# GATECAP_DEMO_DEVICE register map
Stub device the gatecap bus-explorer example explores
Registers are 32-bit, read-only, no defined reset value unless marked. A register's access mark holds for its fields unless they carry their own. Offsets are from the block's base; lines under a group give offsets from that group; [hi:lo] are bit positions; {n}, {i} and the like mark numbered series; 'fields as' and 'values as' point back to an identical list; <NAME> marks a mode.

## Memory map
0x00000000 DEMO — The whole device: one peripheral at address zero

## DEMO — The whole device: one peripheral at address zero
Base 0x00000000
0x00 ID reset 0x5CA1AB1E — Constant identifier
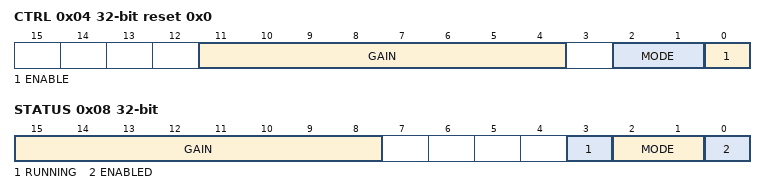
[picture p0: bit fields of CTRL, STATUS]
0x04 CTRL rw reset 0x0 — What the host drives
  [11:4] GAIN — Echoed into STATUS.GAIN
  [2:1] MODE — What the device does when enabled
    0=IDLE; 1=RUN; 2=TEST
  [0] ENABLE — Master enable
0x08 STATUS — What the device makes of CTRL
  [15:8] GAIN
  [3] RUNNING — Enabled and in RUN mode
  [2:1] MODE
  [0] ENABLED
0x0C SCRATCH rw — A plain word, mirrored inverted into MIRROR
0x10 MIRROR — SCRATCH, inverted
0x20 FAULT rw — Always answers pslverr
0x24 SLOW — Answers long after the engine has given up
